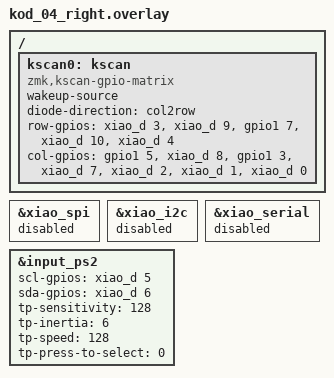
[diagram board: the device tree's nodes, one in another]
/*
 * Copyright (c) 2024 kodomari
 * SPDX-License-Identifier: MIT
 */

#include "kod_04.dtsi"

&xiao_spi { status = "disabled"; };
&xiao_i2c { status = "disabled"; };
&xiao_serial { status = "disabled"; };

/ {
    kscan0: kscan {
        compatible = "zmk,kscan-gpio-matrix";
        wakeup-source;
diode-direction = "col2row";

row-gpios
  = <&xiao_d 3  (GPIO_ACTIVE_HIGH | GPIO_PULL_DOWN)>
  , <&xiao_d 9  (GPIO_ACTIVE_HIGH | GPIO_PULL_DOWN)>
  , <&gpio1 7   (GPIO_ACTIVE_HIGH | GPIO_PULL_DOWN)>
  , <&xiao_d 10 (GPIO_ACTIVE_HIGH | GPIO_PULL_DOWN)>
  , <&xiao_d 4  (GPIO_ACTIVE_HIGH | GPIO_PULL_DOWN)>
  ;

col-gpios
  = <&gpio1 5 GPIO_ACTIVE_HIGH>
  , <&xiao_d 8 GPIO_ACTIVE_HIGH>
  , <&gpio1 3 GPIO_ACTIVE_HIGH>
  , <&xiao_d 7 GPIO_ACTIVE_HIGH>
  , <&xiao_d 2 GPIO_ACTIVE_HIGH>
  , <&xiao_d 1 GPIO_ACTIVE_HIGH>
  , <&xiao_d 0 GPIO_ACTIVE_HIGH>
  ;
};
};


// トラックポイント（PS/2インターフェース）
&input_ps2 {
    status = "okay";
    scl-gpios = <&xiao_d 5 GPIO_ACTIVE_HIGH>;  // CLK: D5 (P0.05)
    sda-gpios = <&xiao_d 6 GPIO_ACTIVE_HIGH>;  // DATA: D6 (P1.11)
    
    // トラックポイント設定
    tp-sensitivity = <128>;   // 感度（0-255、デフォルト128）
    tp-inertia = <6>;         // 慣性（0-255、デフォルト6）
    tp-speed = <128>;         // 速度（0-255、デフォルト128）
    tp-press-to-select = <0>; // Press-to-select無効（既にマウスボタンがある）
};
